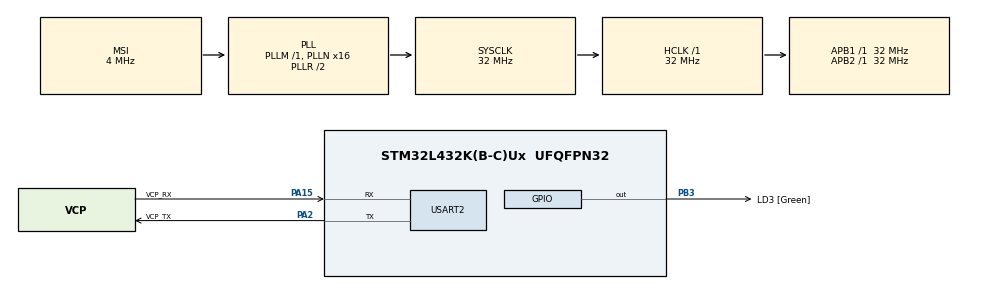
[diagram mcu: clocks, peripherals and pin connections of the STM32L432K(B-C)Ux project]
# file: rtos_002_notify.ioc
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FREERTOS.Tasks01=defaultTask,24,128,StartDefaultTask,Default,NULL,Dynamic,NULL,NULL
FREERTOS.configUSE_NEWLIB_REENTRANT=1
Mcu.Family=STM32L4
Mcu.Name=STM32L432K(B-C)Ux
Mcu.Package=UFQFPN32
NVIC.PriorityGroup=NVIC_PRIORITYGROUP_4
NVIC.TIM6_DAC_IRQn=true\:15\:0\:false\:false\:true\:false\:false\:true\:true
NVIC.TimeBase=TIM6_DAC_IRQn
NVIC.TimeBaseIP=TIM6
PA0.GPIO_Label=MCO [High speed clock in]
PA0.Mode=HSE-External-Clock-Source-for-LittleOrca
PA0.Signal=RCC_CK_IN
PA13\ (JTMS-SWDIO).GPIO_Label=SWDIO
PA13\ (JTMS-SWDIO).Mode=Serial_Wire
PA13\ (JTMS-SWDIO).Signal=SYS_JTMS-SWDIO
PA14\ (JTCK-SWCLK).GPIO_Label=SWCLK
PA14\ (JTCK-SWCLK).Mode=Serial_Wire
PA14\ (JTCK-SWCLK).Signal=SYS_JTCK-SWCLK
PA15\ (JTDI).GPIO_Label=VCP_RX
PA15\ (JTDI).Mode=Asynchronous
PA15\ (JTDI).Signal=USART2_RX
PA2.GPIO_Label=VCP_TX
PA2.Mode=Asynchronous
PA2.Signal=USART2_TX
PB3\ (JTDO-TRACESWO).GPIO_Label=LD3 [Green]
PB3\ (JTDO-TRACESWO).Signal=GPIO_Output
PC14-OSC32_IN\ (PC14).Mode=LSE-External-Oscillator
PC14-OSC32_IN\ (PC14).Signal=RCC_OSC32_IN
PC15-OSC32_OUT\ (PC15).Mode=LSE-External-Oscillator
PC15-OSC32_OUT\ (PC15).Signal=RCC_OSC32_OUT
ProjectManager.HeapSize=0x200
ProjectManager.StackSize=0x400
ProjectManager.TargetToolchain=STM32CubeIDE
RCC.AHBFreq_Value=32000000
RCC.APB1Freq_Value=32000000
RCC.APB1TimFreq_Value=32000000
RCC.APB2Freq_Value=32000000
RCC.APB2TimFreq_Value=32000000
RCC.CortexFreq_Value=32000000
RCC.HCLKFreq_Value=32000000
RCC.HSE_VALUE=8000000
RCC.HSI16_VALUE=16000000
RCC.HSI48_VALUE=48000000
RCC.HSI_VALUE=16000000
RCC.MSI_VALUE=4000000
RCC.PLLMUL=RCC_PLLMUL_4
RCC.PLLN=16
RCC.SYSCLKFreq_VALUE=32000000
RCC.SYSCLKSource=RCC_SYSCLKSOURCE_PLLCLK
RCC.VCOOutputFreq_Value=64000000
USART2.VirtualMode-Asynchronous=VM_ASYNC
VP_FREERTOS_VS_CMSIS_V2.Mode=CMSIS_V2
VP_SYS_VS_tim6.Mode=TIM6
board=NUCLEO-L432KC

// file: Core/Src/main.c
/* USER CODE BEGIN Header */
/**
  ******************************************************************************
  * @file           : main.c
  * @brief          : Main program body
  ******************************************************************************
  * @attention
  *
  * Copyright (c) 2025 STMicroelectronics.
  * All rights reserved.
  *
  * This software is licensed under terms that can be found in the LICENSE file
  * in the root directory of this software component.
  * If no LICENSE file comes with this software, it is provided AS-IS.
  *
  ******************************************************************************
  */
/* USER CODE END Header */
#include "main.h"
#include "cmsis_os.h"

/* USER CODE BEGIN Includes */
#include"stdio.h"
//------------------------THIS IS AN EXAMPLE OF COOPERATIVE SCHEDULING----------------------
/* USER CODE END Includes */

UART_HandleTypeDef huart2;

/* Definitions for defaultTask */
osThreadId_t defaultTaskHandle;
const osThreadAttr_t defaultTask_attributes = {
  .name = "defaultTask",
  .stack_size = 128 * 4,
  .priority = (osPriority_t) osPriorityNormal,
};
/* USER CODE BEGIN PV */
#ifdef _GNUC_
/* With GCC/RAISONANCE, small printf (option LD Linker->Libraries->Small printf
 set to 'Yes') calls __io_putchar() */
#define PUTCHAR_PROTOTYPE int __io_putchar(int ch)
#else
#define PUTCHAR_PROTOTYPE int fputc(int ch, FILE *f)
#endif /* _GNUC_ */

PUTCHAR_PROTOTYPE {
	/* Place your implementation of fputc here */
	/* e.g. write a character to the USART2 and Loop until the end of transmission */
	HAL_UART_Transmit(&huart2, (uint8_t*) &ch, 1, 0xFFFF);
	return ch;
}
/* USER CODE END PV */

void SystemClock_Config(void);
static void MX_GPIO_Init(void);
static void MX_USART2_UART_Init(void);
void StartDefaultTask(void *argument);

/* USER CODE BEGIN PFP */
void Led1_GREEN(void *para1);
void Led2_RED(void *para1);
void Led3_YELLOW(void *para1);
/* USER CODE END PFP */

/* USER CODE BEGIN 0 */
TaskHandle_t redLed_handle=NULL, greenLed_handle=NULL, yellowLed_handle=NULL;
/* USER CODE END 0 */

int main(void)
{
  /* USER CODE BEGIN 1 */

	BaseType_t status;
  /* USER CODE END 1 */

  /* MCU Configuration--------------------------------------------------------*/

  /* Reset of all peripherals, Initializes the Flash interface and the Systick. */
  HAL_Init();

  /* Configure the system clock */
  SystemClock_Config();

  /* Initialize all configured peripherals */
  MX_GPIO_Init();
  MX_USART2_UART_Init();

  /* Init scheduler */
//  osKernelInitialize();

  /* Create the thread(s) */
  /* creation of defaultTask */
//  defaultTaskHandle = osThreadNew(StartDefaultTask, NULL, &defaultTask_attributes);

  /* USER CODE BEGIN RTOS_THREADS */
  /* add threads, ... */
    printf("Hello bro \r\n");
  	HAL_UART_Transmit(&huart2, (uint8_t*)"HELLO\r\n", sizeof("HELLO\r\n"), 1000);

  	status = xTaskCreate(Led1_GREEN, "Green LED", 100, NULL, 1,
  			&greenLed_handle);
  	configASSERT(status== pdPASS);
  	status = xTaskCreate(Led2_RED, "Red LED", 100, NULL, 1, &redLed_handle);
  	configASSERT(status== pdPASS);
  	status = xTaskCreate(Led3_YELLOW, "Yellow LED", 100, NULL, 1,
  			&yellowLed_handle);
  	configASSERT(status== pdPASS);
  	xTaskNotifyGive(greenLed_handle);

  	vTaskStartScheduler();
    printf("The launch of the scheduler has failed\r\n");
  /* USER CODE END RTOS_THREADS */

  /* Start scheduler */
//  osKernelStart();
  /* We should never get here as control is now taken by the scheduler */
  /* Infinite loop */
  while (1)
  {

  }
}

void SystemClock_Config(void)
{
  RCC_OscInitTypeDef RCC_OscInitStruct = {0};
  RCC_ClkInitTypeDef RCC_ClkInitStruct = {0};

  /** Configure the main internal regulator output voltage
  */
  if (HAL_PWREx_ControlVoltageScaling(PWR_REGULATOR_VOLTAGE_SCALE1) != HAL_OK)
  {
    Error_Handler();
  }

  /** Configure LSE Drive Capability
  */
  HAL_PWR_EnableBkUpAccess();
  __HAL_RCC_LSEDRIVE_CONFIG(RCC_LSEDRIVE_LOW);

  /** Initializes the RCC Oscillators according to the specified parameters
  * in the RCC_OscInitTypeDef structure.
  */
  RCC_OscInitStruct.OscillatorType = RCC_OSCILLATORTYPE_LSE|RCC_OSCILLATORTYPE_MSI;
  RCC_OscInitStruct.LSEState = RCC_LSE_ON;
  RCC_OscInitStruct.MSIState = RCC_MSI_ON;
  RCC_OscInitStruct.MSICalibrationValue = 0;
  RCC_OscInitStruct.MSIClockRange = RCC_MSIRANGE_6;
  RCC_OscInitStruct.PLL.PLLState = RCC_PLL_ON;
  RCC_OscInitStruct.PLL.PLLSource = RCC_PLLSOURCE_MSI;
  RCC_OscInitStruct.PLL.PLLM = 1;
  RCC_OscInitStruct.PLL.PLLN = 16;
  RCC_OscInitStruct.PLL.PLLP = RCC_PLLP_DIV7;
  RCC_OscInitStruct.PLL.PLLQ = RCC_PLLQ_DIV2;
  RCC_OscInitStruct.PLL.PLLR = RCC_PLLR_DIV2;
  if (HAL_RCC_OscConfig(&RCC_OscInitStruct) != HAL_OK)
  {
    Error_Handler();
  }

  /** Initializes the CPU, AHB and APB buses clocks
  */
  RCC_ClkInitStruct.ClockType = RCC_CLOCKTYPE_HCLK|RCC_CLOCKTYPE_SYSCLK
                              |RCC_CLOCKTYPE_PCLK1|RCC_CLOCKTYPE_PCLK2;
  RCC_ClkInitStruct.SYSCLKSource = RCC_SYSCLKSOURCE_PLLCLK;
  RCC_ClkInitStruct.AHBCLKDivider = RCC_SYSCLK_DIV1;
  RCC_ClkInitStruct.APB1CLKDivider = RCC_HCLK_DIV1;
  RCC_ClkInitStruct.APB2CLKDivider = RCC_HCLK_DIV1;

  if (HAL_RCC_ClockConfig(&RCC_ClkInitStruct, FLASH_LATENCY_1) != HAL_OK)
  {
    Error_Handler();
  }

  /** Enable MSI Auto calibration
  */
  HAL_RCCEx_EnableMSIPLLMode();
}

static void MX_USART2_UART_Init(void)
{

  huart2.Instance = USART2;
  huart2.Init.BaudRate = 115200;
  huart2.Init.WordLength = UART_WORDLENGTH_8B;
  huart2.Init.StopBits = UART_STOPBITS_1;
  huart2.Init.Parity = UART_PARITY_NONE;
  huart2.Init.Mode = UART_MODE_TX_RX;
  huart2.Init.HwFlowCtl = UART_HWCONTROL_NONE;
  huart2.Init.OverSampling = UART_OVERSAMPLING_16;
  huart2.Init.OneBitSampling = UART_ONE_BIT_SAMPLE_DISABLE;
  huart2.AdvancedInit.AdvFeatureInit = UART_ADVFEATURE_NO_INIT;
  if (HAL_UART_Init(&huart2) != HAL_OK)
  {
    Error_Handler();
  }

}

static void MX_GPIO_Init(void)
{
  GPIO_InitTypeDef GPIO_InitStruct = {0};

  /* GPIO Ports Clock Enable */
  __HAL_RCC_GPIOC_CLK_ENABLE();
  __HAL_RCC_GPIOA_CLK_ENABLE();
  __HAL_RCC_GPIOB_CLK_ENABLE();

  /*Configure GPIO pin Output Level */
  HAL_GPIO_WritePin(LD3_GPIO_Port, LD3_Pin, GPIO_PIN_RESET);

  /*Configure GPIO pin : LD3_Pin */
  GPIO_InitStruct.Pin = LD3_Pin;
  GPIO_InitStruct.Mode = GPIO_MODE_OUTPUT_PP;
  GPIO_InitStruct.Pull = GPIO_NOPULL;
  GPIO_InitStruct.Speed = GPIO_SPEED_FREQ_LOW;
  HAL_GPIO_Init(LD3_GPIO_Port, &GPIO_InitStruct);

}

/* USER CODE BEGIN 4 */
//void Led1_GREEN(void *para1) {
//
//
//	while (1) {
//		printf("Task :led1( green)\r\n");
//		HAL_UART_Transmit(&huart2, (uint8_t*)"Task :led1( green)\r\n",
//				sizeof("Task :led1( green)\r\n"), 1000);
//		vTaskDelay(pdMS_TO_TICKS(1200)); //this is normal delay
//
//	}
//}
//void Led2_RED(void *para1) {
//
//	static uint8_t currentTime=0,prevTime=0;
//	while (1) {
//
//		HAL_UART_Transmit(&huart2,(uint8_t*)"Task :led2(red)called \r\n",sizeof("Task :led2(red)called \r\n"), 1000);
//		vTaskDelay(pdMS_TO_TICKS(750));
//
//	}
//}
//void Led3_YELLOW(void *para1) {
//
//	while (1) {
//
//		HAL_UART_Transmit(&huart2,(uint8_t*) "Task :led3(yellow)\r\n",
//				sizeof("Task :led3(yellow)\r\n"), 1000);
//		vTaskDelay(pdMS_TO_TICKS(600));
//
//
//	}
//}

void Led1_GREEN(void *para1) {
	while (1) {
		ulTaskNotifyTake(pdTRUE, portMAX_DELAY); // Wait for signal
//		printf("Task :led1( green)\r\n");
		HAL_UART_Transmit(&huart2, (uint8_t*)"Task :led1( green)\r\n",
				sizeof("Task :led1( green)\r\n"), 1000);
		vTaskDelay(pdMS_TO_TICKS(100)); // Optional small delay
		xTaskNotifyGive(redLed_handle); // Trigger Task 2
	}
}

void Led2_RED(void *para1) {
	while (1) {
		ulTaskNotifyTake(pdTRUE, portMAX_DELAY);
		HAL_UART_Transmit(&huart2,(uint8_t*)"Task :led2(red)called \r\n",
			sizeof("Task :led2(red)called \r\n"), 1000);
		vTaskDelay(pdMS_TO_TICKS(100));
		xTaskNotifyGive(yellowLed_handle); // Trigger Task 3
	}
}

void Led3_YELLOW(void *para1) {
	while (1) {
		ulTaskNotifyTake(pdTRUE, portMAX_DELAY);
		HAL_UART_Transmit(&huart2,(uint8_t*) "Task :led3(yellow)\r\n",
				sizeof("Task :led3(yellow)\r\n"), 1000);
		vTaskDelay(pdMS_TO_TICKS(100));
		xTaskNotifyGive(greenLed_handle); // Loop back to Task 1
	}
}

/* USER CODE END 4 */

void StartDefaultTask(void *argument)
{
  for(;;)
  {
    osDelay(1);
  }
}

void HAL_TIM_PeriodElapsedCallback(TIM_HandleTypeDef *htim)
{
  if (htim->Instance == TIM6) {
    HAL_IncTick();
  }
}

void Error_Handler(void)
{
  __disable_irq();
  while (1)
  {
  }
}
